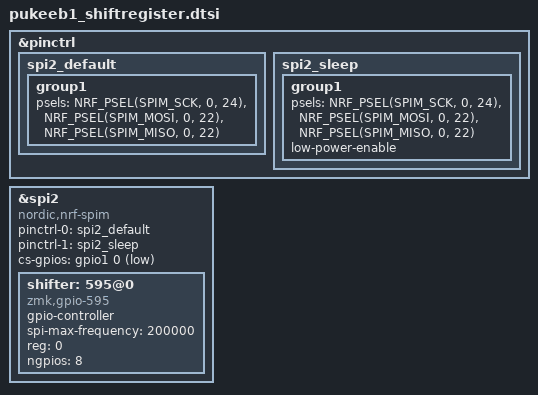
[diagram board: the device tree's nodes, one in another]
&pinctrl {
    spi2_default: spi2_default {
        group1 {
            psels = <NRF_PSEL(SPIM_SCK, 0, 24)>,
                <NRF_PSEL(SPIM_MOSI, 0, 22)>,
                <NRF_PSEL(SPIM_MISO, 0, 22)>;
        };
    };

    spi2_sleep: spi2_sleep {
        group1 {
            psels = <NRF_PSEL(SPIM_SCK, 0, 24)>,
                <NRF_PSEL(SPIM_MOSI, 0, 22)>,
                <NRF_PSEL(SPIM_MISO, 0, 22)>;
            low-power-enable;
        };
    };
};

&spi2 {
    status = "okay";
    compatible = "nordic,nrf-spim";
    pinctrl-0 = <&spi2_default>;
    pinctrl-1 = <&spi2_sleep>;
    pinctrl-names = "default", "sleep";
    // cs-gpios =  <&gpio1 0 GPIO_ACTIVE_LOW>, <&gpio0 17 GPIO_ACTIVE_LOW>;
    cs-gpios =  <&gpio1 0 GPIO_ACTIVE_LOW>;

    shifter: 595@0 {
        compatible = "zmk,gpio-595";
        status = "okay";
        gpio-controller;
        spi-max-frequency = <200000>;
        reg = <0>;
        #gpio-cells = <2>;
        ngpios = <8>;
    };

    // oled: ssd1306@1{
    //     compatible = "solomon,ssd1306fb";
    //     data_cmd-gpios = <&gpio0 20 GPIO_ACTIVE_HIGH>;
    //     // reg = <0x3c>;
    //     spi-max-frequency = <200000>;
    //     reg = <1>;
    //     width = <128>;
    //     height = <64>;
    //     segment-offset = <0>;
    //     page-offset = <0>;
    //     display-offset = <0>;
    //     multiplex-ratio = <31>;
    //     segment-remap;
    //     com-invdir;
    //     com-sequential;
    //     inversion-on;
    //     prechargep = <0x22>;
    // };
};
